# R7FA2T107 register map
Vendor: Renesas Electronics Corporation; Series: RA2; File version: 1.00.00
CPU: CM23 r1p0, little endian, MPU, no FPU, VTOR, 2 interrupt priority bits, 32 interrupts
Registers are 8-bit, read-write, reset 0x0 unless marked. A register's access mark holds for its fields unless they carry their own. Offsets are from the block's base; [hi:lo] are bit positions; 'fields as' and 'values as' point back to an identical list.

## ACMPHS — High-Speed Analog Comparator
Base 0x40085E00
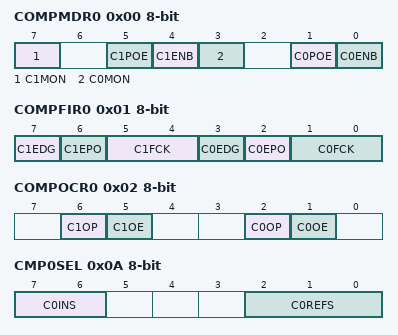
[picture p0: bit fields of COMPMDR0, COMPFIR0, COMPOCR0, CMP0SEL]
0x00 COMPMDR0 — ACMPHS Mode Setting Register 0
  [7] C1MON ro — Monitoring flag of comparator 1
    0=The input voltage of comparator 1 is lower than the reference voltage of comparator 1, or comparator 1 is stopped; 1=The input voltage of comparator 1 is greater than the reference voltage of comparator 1
  [5] C1POE — ACMPHS1 VCOUT Pin Output Enable
    0=Output of the result from comparator 1 on the VCOUT1 is disabled; 1=Output of the result from comparator 1 on the VCOUT1 is enabled
  [4] C1ENB — Enabling operation of comparator 1
    0=The operation of comparator 1 is disabled; 1=The operation of comparator 1 is enabled
  [3] C0MON ro — Monitoring flag of comparator 0
    0=The input voltage of comparator 0 is lower than the reference voltage of comparator 0, or comparator 0 is stopped; 1=The input voltage of comparator 0 is greater than the reference voltage of comparator 0
  [1] C0POE — ACMPHS0 VCOUT Pin Output Enable
    0=Output of the result from comparator 0 on the VCOUT0 is disabled; 1=Output of the result from comparator 0 on the VCOUT0 is enabled
  [0] C0ENB — Enabling operation of comparator 0
    0=The operation of comparator 0 is disabled; 1=The operation of comparator 0 is enabled
0x01 COMPFIR0 — ACMPHS Filter Control Register 0
  [7] C1EDG — Selecting the edge detection for comparator 1
    0=Interrupt and ELC event request by one-edge detection; 1=Interrupt and ELC event request by both-edge detection
  [6] C1EPO — Switching the edge sense of comparator 1
    0=Interrupt and ELC event request on rising edge; 1=Interrupt and ELC event request on falling edge
  [5:4] C1FCK — Selecting the filter for comparator 1
    0=The filter for comparator 1 is disabled; 1=The filter for comparator 1 is enabled, and sampling proceeds at a cycle of PCLKB; 2=The filter for comparator 1 is enabled, and sampling proceeds at a cycle of PCLKB/8; 3=Setting prohibited
  [3] C0EDG — Selecting the edge detection for comparator 0
    values as C1EDG
  [2] C0EPO — Switching the edge sense of comparator 0
    values as C1EPO
  [1:0] C0FCK — Selecting the filter for comparator 0
    0=The filter for comparator 0 is disabled; 1=The filter for comparator 0 is enabled, and sampling proceeds at a cycle of PCLKB; 2=The filter for comparator 0 is enabled, and sampling proceeds at a cycle of PCLKB/8; 3=Setting prohibited
0x02 COMPOCR0 — ACMPHS Output Control Register 0
  [6] C1OP — ACMPHS1 VCOUT Output Polarity Selection
    0=The output of comparator 1 is output to VCOUT1; 1=The inverted output of comparator 1 is output to VCOUT1
  [5] C1OE — ACMPHS1 VCOUT Pin Output Enable
    values as COMPMDR0.C1POE
  [2] C0OP — ACMPHS0 VCOUT Output Polarity Selection
    0=The output of comparator 0 is output to VCOUT0; 1=The inverted output of comparator 0 is output to VCOUT0
  [1] C0OE — ACMPHS0 VCOUT Pin Output Enable
    values as COMPMDR0.C0POE
0x0A CMP0SEL — Comparator 0 Input Signal Selection Control Register
  [7:6] C0INS — Selecting the input signal on the positive side of comparator 0
    0=External pin (CMPIN01) is selected; 1=External pin (CMPIN02) is selected; 2=External pin (CMPIN03) is selected; 3=The external reference voltage (CMPREF0) is selected
  [2:0] C0REFS — Selecting the input signal on the negative side of comparator 0
    0=The external reference voltage (CMPREF0) is selected; 1=External pin (CMPIN01) is selected; 2=External pin (CMPIN02) is selected; 3=External pin (CMPIN03) is selected; 4=Select internal reference voltage (Vref) as ACMPHS0 reference voltage; other=Others (Setting prohibited)
0x0B CMP1SEL — Comparator 1 Input Signal Selection Control Register
  [1:0] C1REFS — Selecting the input signal on the negative side of comparator 1
    0=The external reference voltage (CMPREF1) is selected; 1=Select internal reference voltage (Vref) as ACMPHS1 reference voltage; other=Others (Setting prohibited)
